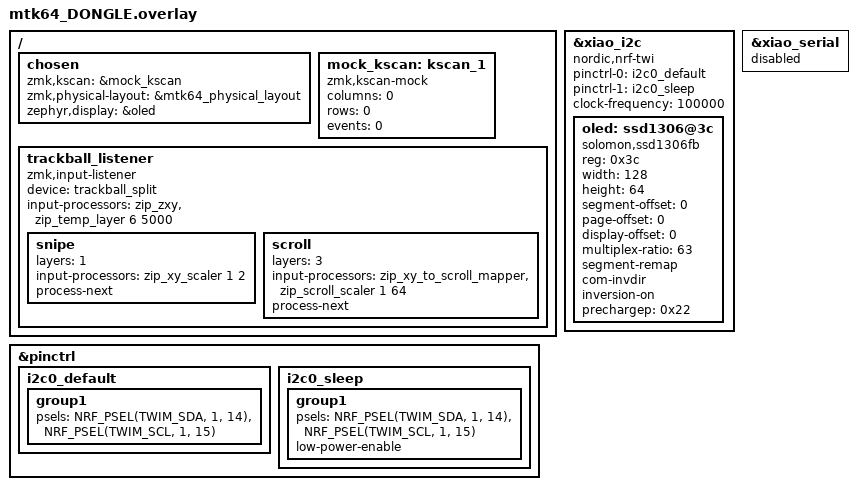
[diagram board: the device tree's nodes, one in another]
#include "mtk64.dtsi"
#include "mtk64_trackball.dtsi"

/ {
    chosen {
        zmk,kscan = &mock_kscan;
        zmk,physical-layout = &mtk64_physical_layout;
        zephyr,display = &oled;
    };

    mock_kscan: kscan_1 {
        compatible = "zmk,kscan-mock";
        columns = <0>;
        rows = <0>;
        events = <0>;
    };
};

/ {
    trackball_listener: trackball_listener {
        compatible = "zmk,input-listener";
        status = "okay";
        device = <&trackball_split>;
        input-processors = <&zip_zxy>, <&zip_temp_layer 6 5000>;

        snipe {
            layers = <1>;
            input-processors = <&zip_xy_scaler 1 2>;
            process-next;
        };

        scroll {
            layers = <3>;
            input-processors = <&zip_xy_to_scroll_mapper>, <&zip_scroll_scaler 1 64>;
            process-next;
        };
    };
};

&pinctrl {
    i2c0_default: i2c0_default {
        group1 {
            psels = <NRF_PSEL(TWIM_SDA, 1, 14)>,
                    <NRF_PSEL(TWIM_SCL, 1, 15)>;
        };
    };

    i2c0_sleep: i2c0_sleep {
        group1 {
            psels = <NRF_PSEL(TWIM_SDA, 1, 14)>,
                    <NRF_PSEL(TWIM_SCL, 1, 15)>;
            low-power-enable;
        };
    };
};

&xiao_i2c {
    status = "okay";
    compatible = "nordic,nrf-twi";
    pinctrl-0 = <&i2c0_default>;
    pinctrl-1 = <&i2c0_sleep>;
    pinctrl-names = "default", "sleep";
    clock-frequency = <100000>;

    oled: ssd1306@3c {
        compatible = "solomon,ssd1306fb";
        reg = <0x3c>;
        width = <128>;
        height = <64>;
        segment-offset = <0>;
        page-offset = <0>;
        display-offset = <0>;
        multiplex-ratio = <63>;
        segment-remap;
        com-invdir;
        inversion-on;
        prechargep = <0x22>;
    };
}; 

&xiao_serial { status = "disabled"; };
